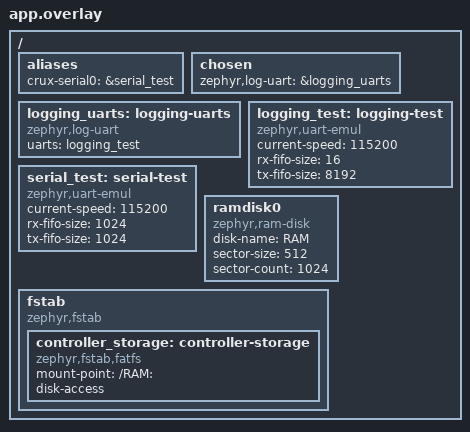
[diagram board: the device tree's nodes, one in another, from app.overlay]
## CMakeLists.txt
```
# SPDX-License-Identifier: Apache-2.0

# The fixture product's application on native_sim. It is built in its own west workspace, where
# crux-controller is a project and so a Zephyr module that west finds: this file names no path,
# source or include directory of crux-controller and adds no module. It links the interface target
# of the framework and calls the framework's image function, as a product image does.

cmake_minimum_required(VERSION 3.20.0)
find_package(Zephyr REQUIRED HINTS $ENV{ZEPHYR_BASE})
project(controller_product_integration LANGUAGES C)

if(NOT CONFIG_BOARD_NATIVE_SIM OR NOT CONFIG_FAKE_ENTROPY_NATIVE_SIM)
    message(FATAL_ERROR "The fixture product is restricted to native_sim: its entropy source is a test source")
endif()
# An unmet Kconfig dependency only warns, and would build an image without the service.
if(NOT CONFIG_ZEPHYR_CRUX_CONTROLLER_MODULE OR NOT CONFIG_CRUX_CONTROLLER_FRAMEWORK
   OR NOT CONFIG_CRUX_CONTROLLER_FRAMEWORK_MANAGEMENT OR NOT CONFIG_CRUX_CONTROLLER_FRAMEWORK_CLI_SERIAL
   OR NOT CONFIG_CRUX_CONTROLLER_FRAMEWORK_TIME_SYNC)
    message(FATAL_ERROR "The fixture product needs the framework module with web management, the serial "
                        "command line and time synchronisation")
endif()

target_sources(app PRIVATE src/test_product_import.c)
target_link_libraries(app PRIVATE controller::framework)
controller_framework_image()
```

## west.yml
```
# SPDX-License-Identifier: Apache-2.0
# The west manifest of the fixture product: a product repository that imports this repository the way
# a product does, as the manifest repository of its own workspace (west's T2 topology). It lists
# crux-controller and imports its manifest, which brings Crux at the commit that west.yml of
# crux-controller pins, its narrowed import and its other projects. The framework is found as a
# Zephyr module of the workspace; the product names no path of crux-controller.
#
# run.sh copies this folder into a new workspace and writes the commit under test into the copy as
# the revision of crux-controller. The value below is only what a product would start from.
manifest:
  version: "1.2"

  remotes:
    - name: wonny-labs
      url-base: https://github.com/wonny-labs

  projects:
    - name: crux-controller
      remote: wonny-labs
      revision: main
      import: true

  self:
    path: product
```

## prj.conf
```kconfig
# The configuration of the fixture product: the controller framework with web management, the serial
# command line and time synchronisation on native_sim, as a product that imports this repository sets
# it. The values are those of the base scenario (tests/framework/base/prj.conf), copied, because a
# product keeps its own configuration and does not read the tests of the framework.
# west spdx needs zephyr.meta, which Zephyr writes only with this option.
CONFIG_BUILD_OUTPUT_META=y
CONFIG_CRUX_CONTROLLER_FRAMEWORK=y
CONFIG_SNTP=y
CONFIG_CRUX_CONTROLLER_TIME_SERVER="127.0.0.1"

CONFIG_CRUX_SERIAL=y
CONFIG_CRUX_CLI=y
CONFIG_CRUX_CLI_CONSOLE=y
CONFIG_CRUX_CLI_CONSOLE_PRIORITY=11
CONFIG_UART_INTERRUPT_DRIVEN=y
CONFIG_UART_USE_RUNTIME_CONFIGURE=y

CONFIG_ZTEST=y
CONFIG_ZTEST_VERIFY_RUN_ALL=n
CONFIG_STD_C17=y
CONFIG_EMUL=y
CONFIG_UART_EMUL=y
CONFIG_IRQ_OFFLOAD=y
# The web adapter refuses the external libc of native_sim; the management scenario runs on picolibc.
CONFIG_PICOLIBC=y
# One thread of the test runs the start sequence (key generation, signing, the format of the RAM
# disk) and the TLS client. Not measured.
CONFIG_MAIN_STACK_SIZE=32768
CONFIG_ZTEST_STACK_SIZE=32768
CONFIG_HEAP_MEM_POOL_SIZE=32768

# The Mbed TLS profile of app/conf/management.conf, as a copy: this scenario has no Kconfig of the product,
# as in the management scenario. The heap is larger than the product's 120,000 bytes,
# because the TLS client of the test runs in the same process and takes up to one more connection
# and its own handshake. The product declares 120,000 bytes for three server connections of 34,912
# bytes, a handshake of 3,576 bytes and the other PSA users, and 180,000 leaves about 25,000 bytes
# over the worst concurrent case that this process can reach. A paper figure, not measured.
CONFIG_MBEDTLS=y
CONFIG_MBEDTLS_PSA_CRYPTO_C=y
CONFIG_PSA_CRYPTO_PROVIDER_MBEDTLS=y
CONFIG_MBEDTLS_ENABLE_HEAP=y
CONFIG_MBEDTLS_HEAP_SIZE=180000
CONFIG_MBEDTLS_SSL_IN_CONTENT_LEN=16384
CONFIG_MBEDTLS_SSL_OUT_CONTENT_LEN=16384
CONFIG_MBEDTLS_SSL_PROTO_TLS1_2=y
CONFIG_MBEDTLS_SSL_PROTO_TLS1_3=y
CONFIG_MBEDTLS_SSL_TLS1_3_KEY_EXCHANGE_MODE_EPHEMERAL_ENABLED=y
CONFIG_MBEDTLS_KEY_EXCHANGE_ECDHE_ECDSA_ENABLED=y
CONFIG_MBEDTLS_CIPHERSUITE_TLS_ECDHE_ECDSA_WITH_AES_128_GCM_SHA256=y
CONFIG_MBEDTLS_CIPHERSUITE_TLS1_3_AES_128_GCM_SHA256=y
CONFIG_PSA_WANT_ALG_SHA_256=y
CONFIG_PSA_WANT_ECC_SECP_R1_256=y
CONFIG_PSA_WANT_ALG_ECDSA=y
CONFIG_PSA_WANT_ALG_ECDH=y
CONFIG_PSA_WANT_ALG_GCM=y
CONFIG_PSA_WANT_KEY_TYPE_AES=y
CONFIG_PSA_WANT_ALG_HMAC=y
CONFIG_PSA_WANT_KEY_TYPE_HMAC=y
CONFIG_PSA_WANT_ALG_HKDF=y
CONFIG_PSA_WANT_ALG_PBKDF2_HMAC=y
CONFIG_PSA_WANT_ALG_TLS12_PRF=y
CONFIG_PSA_WANT_KEY_TYPE_ECC_PUBLIC_KEY=y
CONFIG_PSA_WANT_KEY_TYPE_ECC_KEY_PAIR_IMPORT=y
CONFIG_PSA_WANT_KEY_TYPE_ECC_KEY_PAIR_EXPORT=y
CONFIG_PSA_WANT_KEY_TYPE_ECC_KEY_PAIR_GENERATE=y
CONFIG_PSA_WANT_KEY_TYPE_ECC_KEY_PAIR_DERIVE=y
CONFIG_MBEDTLS_PK_WRITE_C=y
CONFIG_CRUX_PSA_THREADING=y

# The Crux services, as in app/conf/management.conf. The module selects Thread, Sync and Time for them.
CONFIG_CRUX_ACCESS=y
CONFIG_CRUX_CONFIG_SERVICE=y
CONFIG_CRUX_MGMT_STATUS=y
CONFIG_CRUX_TLS_CERTIFICATE=y
CONFIG_CRUX_WEB=y
CONFIG_CRUX_WEB_SESSION=y
CONFIG_CRUX_WEB_MANAGEMENT=y
CONFIG_CRUX_SYSTEM=y
CONFIG_CRUX_NETIF=y
CONFIG_WATCHDOG=y
CONFIG_HWINFO=y
CONFIG_REBOOT=y

# The listener binds the loopback address, and the TLS client of the test is in the same process. The
# listener opens on Zephyr's own thread, so the client retries its connect.
CONFIG_CRUX_WEB_PORT=443
CONFIG_CRUX_WEB_BIND_ADDRESS="127.0.0.1"
CONFIG_CRUX_WEB_BACKLOG=4
CONFIG_HTTP_SERVER_MAX_CLIENTS=3
CONFIG_HTTP_SERVER_STACK_SIZE=16384
CONFIG_CRUX_WEB_SESSION_WORKER_PRIORITY=11
CONFIG_CRUX_WEB_MANAGEMENT_WORKER_PRIORITY=11
CONFIG_CRUX_SECURITY_EVENT_DRAIN_PRIORITY=11

# The simulator's fake entropy source: test-only, so nothing made here is a secret.
CONFIG_ENTROPY_GENERATOR=y

# Crux File on a RAM disk with the simulator provider, and the formatting service that the zone
# uses when the blank disk does not mount.
CONFIG_FILE_SYSTEM=y
CONFIG_FILE_SYSTEM_MKFS=y
CONFIG_FAT_FILESYSTEM_ELM=y
CONFIG_FS_FATFS_LFN=y
CONFIG_FS_FATFS_LFN_MODE_STACK=y
CONFIG_FS_FATFS_MAX_LFN=127
CONFIG_FS_FATFS_MOUNT_MKFS=n
CONFIG_FS_FATFS_REENTRANT=y
CONFIG_FS_FATFS_NUM_FILES=6
CONFIG_DISK_DRIVERS=y
CONFIG_DISK_DRIVER_RAM=y
CONFIG_CRUX_FILE_FATFS_SIMULATOR=y

# The network: Zephyr's loopback interface, TCP and the TLS socket layer, with no host network.
CONFIG_NETWORKING=y
CONFIG_NET_IPV4=y
CONFIG_NET_IPV6=n
CONFIG_NET_TCP=y
CONFIG_NET_UDP=y
CONFIG_NET_SOCKETS=y
CONFIG_NET_DRIVERS=y
CONFIG_NET_LOOPBACK=y
CONFIG_NET_SOCKETS_SOCKOPT_TLS=y
CONFIG_TLS_CREDENTIALS=y
CONFIG_TLS_MAX_CREDENTIALS_NUMBER=4
CONFIG_NET_SOCKETS_TLS_MAX_CONTEXTS=6
CONFIG_ZVFS_OPEN_MAX=48
CONFIG_ZVFS_POLL_MAX=24
CONFIG_ZVFS_EVENTFD=y
CONFIG_NET_MAX_CONTEXTS=32
CONFIG_NET_MAX_CONN=32
CONFIG_NET_PKT_RX_COUNT=64
CONFIG_NET_PKT_TX_COUNT=64
CONFIG_NET_BUF_RX_COUNT=256
CONFIG_NET_BUF_TX_COUNT=256

# Crux Logging writes to an emulated UART, so that the test can read what it wrote.
CONFIG_CRUX_LOGGING=y
CONFIG_SERIAL=y
CONFIG_LOG=y
CONFIG_LOG_MODE_DEFERRED=y
CONFIG_LOG_MODE_OVERFLOW=n
CONFIG_LOG_BLOCK_IN_THREAD=n
CONFIG_LOG_PROCESS_THREAD=y
CONFIG_LOG_PROCESS_THREAD_STACK_SIZE=2048
CONFIG_LOG_PROCESS_THREAD_CUSTOM_PRIORITY=y
CONFIG_LOG_PROCESS_THREAD_PRIORITY=14
CONFIG_LOG_BUFFER_SIZE=8192
CONFIG_LOG_MAX_LEVEL=4
CONFIG_LOG_DEFAULT_LEVEL=0
CONFIG_LOG_RUNTIME_FILTERING=n
CONFIG_LOG_BACKEND_UART=y
CONFIG_LOG_BACKEND_NATIVE_POSIX=n
CONFIG_LOG_BACKEND_UART_ASYNC=n
CONFIG_LOG_PRINTK=n
CONFIG_SHELL_LOG_BACKEND=n
CONFIG_LOG_BACKEND_SHOW_LEVEL=y
CONFIG_LOG_BACKEND_CRLF_NONE=n
CONFIG_THREAD_MONITOR=y
CONFIG_THREAD_NAME=y
# An image with Crux management must not enable the Zephyr shell.
CONFIG_SHELL=n

# Health supervision, which the application interface needs, in the production watchdog
# configuration of the base image: the task watchdog without a hardware fallback. native_sim has no
# watchdog behind the alias crux-watchdog0 here, so the watchdog is not armed; the start without a
# watchdog of decision D14 lets this development build start the product's application.
CONFIG_TASK_WDT=y
CONFIG_TASK_WDT_HW_FALLBACK=n
CONFIG_CRUX_CONTROLLER_START_WITHOUT_WATCHDOG=y
```

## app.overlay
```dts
/* SPDX-License-Identifier: Apache-2.0 */
/* The devicetree of the fixture product on native_sim, as in the base scenario
 * (tests/framework/base/app.overlay): Crux Logging on one emulated UART, the Crux serial console on
 * a second one (alias crux-serial0), and a RAM disk with the fstab entry controller_storage that
 * the framework mounts. */
/ {
    aliases { crux-serial0 = &serial_test; };
    chosen { zephyr,log-uart = &logging_uarts; };
    logging_uarts: logging-uarts {
        compatible = "zephyr,log-uart";
        uarts = <&logging_test>;
    };
    logging_test: logging-test {
        compatible = "zephyr,uart-emul";
        current-speed = <115200>;
        rx-fifo-size = <16>;
        tx-fifo-size = <8192>;
        status = "okay";
    };
    serial_test: serial-test {
        compatible = "zephyr,uart-emul";
        current-speed = <115200>;
        rx-fifo-size = <1024>;
        tx-fifo-size = <1024>;
        status = "okay";
    };

    ramdisk0 {
        compatible = "zephyr,ram-disk";
        disk-name = "RAM";
        sector-size = <512>;
        sector-count = <1024>;
    };

    fstab {
        compatible = "zephyr,fstab";
        controller_storage: controller-storage {
            compatible = "zephyr,fstab,fatfs";
            mount-point = "/RAM:";
            disk-access;
        };
    };
};
```

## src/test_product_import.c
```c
/* SPDX-License-Identifier: Apache-2.0 */

/* The fixture product's test: the framework, imported into a west workspace of its own, starts its
 * services on native_sim. The product reaches the framework through <controller/framework.h> and
 * its Kconfig symbols only. The test reads what Crux Logging wrote to an emulated UART and what the
 * Crux serial console wrote to another.
 *
 * The cases run in order, in one image, because the start function runs once per program. The
 * behaviour of each service is the subject of the scenarios of crux-controller; this test shows
 * that a product that imports the framework builds it and runs it, and that its main() passes a
 * descriptor with the four entries of the application interface (criterion 14, delivery stage 3).
 * The product's application here does nothing in its entries; the fixture application of
 * crux-controller's tests/framework exercises the interface. */

#include <stdbool.h>
#include <stddef.h>
#include <stdint.h>
#include <string.h>

#include <controller/framework.h>
#include <zephyr/device.h>
#include <zephyr/drivers/serial/uart_emul.h>
#include <zephyr/kernel.h>
#include <zephyr/logging/log_ctrl.h>
#include <zephyr/ztest.h>

#define LOG_UART DEVICE_DT_GET(DT_NODELABEL(logging_test))
#define CONSOLE_UART DEVICE_DT_GET(DT_NODELABEL(serial_test))
#define CONSOLE_POLL_MS 10
#define CONSOLE_ATTEMPTS 1000

static char log_text[8192];
static size_t log_length;

/* Everything that Crux Logging wrote since the last call, appended to what was read before. */
static const char *drain_log(void)
{
    log_flush();
    log_length += uart_emul_get_tx_data(LOG_UART, (uint8_t *)log_text + log_length,
                                        sizeof log_text - 1u - log_length);
    log_text[log_length] = '\0';
    return log_text;
}

/* The product's application: the four mandatory entries, each succeeding at once. */
static int product_init(controller_app_context_t *context)
{
    ARG_UNUSED(context);
    return 0;
}

static int product_start(controller_app_context_t *context)
{
    ARG_UNUSED(context);
    return 0;
}

static int product_stop(controller_app_context_t *context, controller_app_stop_reason_t reason)
{
    ARG_UNUSED(context);
    ARG_UNUSED(reason);
    return 0;
}

static void product_safe_state(controller_app_context_t *context)
{
    ARG_UNUSED(context);
}

static const controller_app_t product_application = {
    .init = product_init,
    .start = product_start,
    .stop = product_stop,
    .safe_state = product_safe_state,
    .user_data = NULL,
};

ZTEST_SUITE(product, NULL, NULL, NULL, NULL, NULL);

ZTEST(product, test_01_the_imported_framework_starts_every_phase)
{
    zassert_equal(controller_framework_start(&product_application), CONTROLLER_FRAMEWORK_OK);
    const char *log = drain_log();

    zassert_not_null(strstr(log, "phase clock ok"), "%s", log);
    zassert_not_null(strstr(log, "phase web management ok"), "%s", log);
    zassert_not_null(strstr(log, "phase command line ok"), "%s", log);
    zassert_not_null(strstr(log, "phase time synchronisation ok"), "%s", log);
    /* With health supervision and the application: clock, supervisor, storage access, app init,
     * web management, command line, time synchronisation, start prerequisites and application. */
    zassert_not_null(strstr(log, "phase app init ok"), "%s", log);
    zassert_not_null(strstr(log, "application started state=running"), "%s", log);
    zassert_not_null(strstr(log, "startup done phases=9 failed=0"), "%s", log);
}

ZTEST(product, test_02_a_second_start_is_refused)
{
    zassert_equal(controller_framework_start(&product_application),
                  CONTROLLER_FRAMEWORK_ERR_ALREADY_STARTED);
}

ZTEST(product, test_03_the_serial_console_prompts_for_a_login)
{
    char text[64];
    size_t length = 0u;

    zassert_true(device_is_ready(CONSOLE_UART));
    for (int attempt = 0; attempt < CONSOLE_ATTEMPTS; attempt++) {
        length += uart_emul_get_tx_data(CONSOLE_UART, (uint8_t *)text + length,
                                        sizeof text - 1u - length);
        text[length] = '\0';
        if (strstr(text, "login: ") != NULL) {
            return;
        }
        k_msleep(CONSOLE_POLL_MS);
    }
    zassert_unreachable("the console did not prompt; it wrote \"%s\"", text);
}
```
